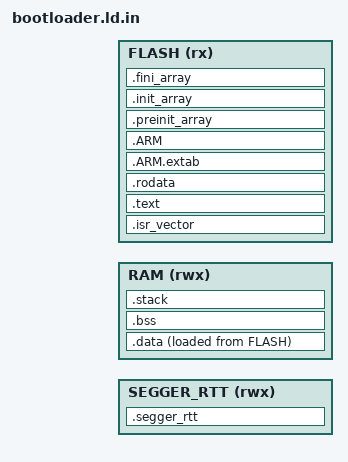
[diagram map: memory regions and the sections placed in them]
ENTRY(Reset_Handler)

_STACK_SIZE = 0x1000;

MEMORY
{
	SEGGER_RTT (rwx): ORIGIN = @SEGGER_RTT_START@, LENGTH = @SEGGER_RTT_SIZE@
	RAM        (rwx): ORIGIN = @BL_RAM_START@,     LENGTH = @BL_RAM_SIZE@
	FLASH      (rx):  ORIGIN = @BL_FLASH_START@,   LENGTH = @BL_FLASH_SIZE@
}

SECTIONS
{
	.isr_vector :
	{
		. = ALIGN(8);
		KEEP(*(.isr_vector))
		. = ALIGN(8);
	} > FLASH

	.text :
	{
		. = ALIGN(8);
		*(.text)
		*(.text*)
		*(.glue_7)
		*(.glue_7t)
		*(.eh_frame)
		KEEP (*(.init))
		KEEP (*(.fini))
		. = ALIGN(8);
		_etext = .;
	} > FLASH

	.rodata :
	{
		. = ALIGN(8);
		*(.rodata)
		*(.rodata*)
		. = ALIGN(8);
	} > FLASH

	.ARM.extab (READONLY) :
	{
		. = ALIGN(8);
		*(.ARM.extab* .gnu.linkonce.armextab.*)
		. = ALIGN(8);
	} > FLASH

	.ARM (READONLY) :
	{
		. = ALIGN(8);
		__exidx_start = .;
		*(.ARM.exidx*)
		__exidx_end = .;
		. = ALIGN(8);
	} > FLASH

	.preinit_array (READONLY) :
	{
		. = ALIGN(8);
		PROVIDE_HIDDEN (__preinit_array_start = .);
		KEEP (*(.preinit_array*))
		PROVIDE_HIDDEN (__preinit_array_end = .);
		. = ALIGN(8);
	} > FLASH

	.init_array (READONLY) :
	{
		. = ALIGN(8);
		PROVIDE_HIDDEN (__init_array_start = .);
		KEEP (*(SORT(.init_array.*)))
		KEEP (*(.init_array*))
		PROVIDE_HIDDEN (__init_array_end = .);
		. = ALIGN(8);
	} > FLASH

	.fini_array (READONLY) :
	{
		. = ALIGN(8);
		PROVIDE_HIDDEN (__fini_array_start = .);
		KEEP (*(SORT(.fini_array.*)))
		KEEP (*(.fini_array*))
		PROVIDE_HIDDEN (__fini_array_end = .);
		. = ALIGN(8);
	} > FLASH

	_sidata = LOADADDR(.data);

	.data :
	{
		. = ALIGN(8);
		_sdata = .;
		*(.data)	
		*(.data*) 
		*(.RamFunc)
		*(.RamFunc*)
		. = ALIGN(8);
		_edata = .;
	} > RAM AT > FLASH

	.bss :
	{
		. = ALIGN(8);
		_sbss = .;
		*(.bss)
		*(.bss*)
		*(COMMON)
		. = ALIGN(8);
		_ebss = .;
	} > RAM

	.stack :
	{
		. = ALIGN(8);
		PROVIDE ( end = . );
		PROVIDE ( _end = . );
		. = . + _STACK_SIZE;
		_estack = .;
		. = ALIGN(8);
	} > RAM

	/DISCARD/ :
	{
		libc.a ( * )
		libm.a ( * )
		libgcc.a ( * )
	}

	.ARM.attributes 0 :
	{
		*(.ARM.attributes)
	}

	.segger_rtt :
	{
		KEEP(*(.segger_rtt))
	} > SEGGER_RTT
}
